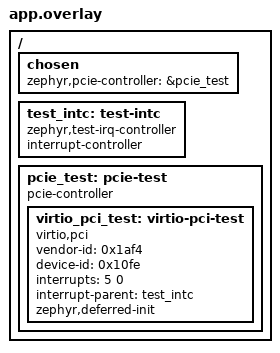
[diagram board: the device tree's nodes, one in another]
/*
 * SPDX-FileCopyrightText: Copyright The Zephyr Project Contributors
 *
 * SPDX-License-Identifier: Apache-2.0
 */

/ {
	chosen {
		zephyr,pcie-controller = &pcie_test;
	};

	test_intc: test-intc {
		compatible = "zephyr,test-irq-controller";
		interrupt-controller;
		#interrupt-cells = <2>;
	};

	pcie_test: pcie-test {
		compatible = "pcie-controller";
		#address-cells = <1>;
		#size-cells = <1>;

		virtio_pci_test: virtio-pci-test {
			compatible = "virtio,pci";
			vendor-id = <0x1af4>;
			device-id = <0x10fe>;
			interrupts = <5 0>;
			interrupt-parent = <&test_intc>;
			zephyr,deferred-init;
			status = "okay";
		};
	};
};
